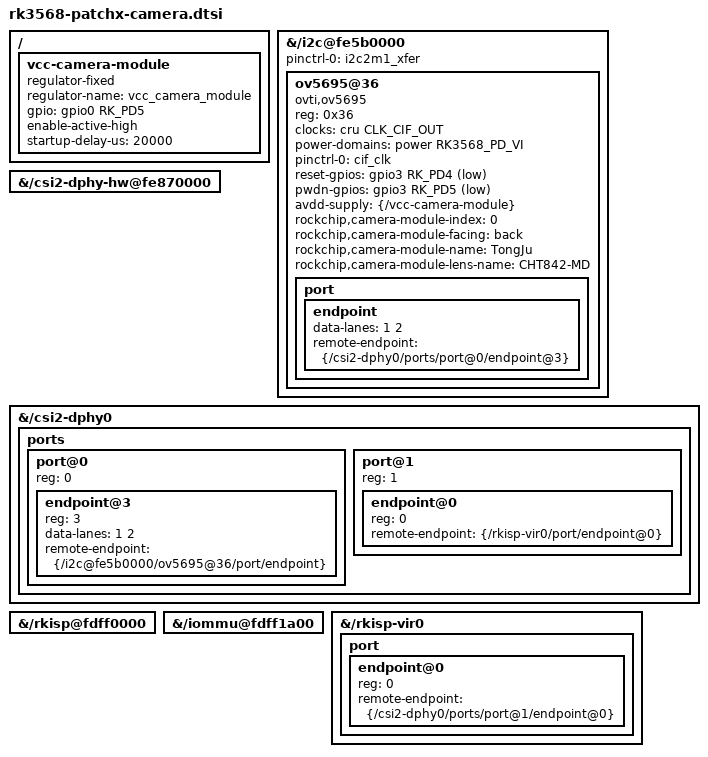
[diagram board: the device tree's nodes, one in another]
// SPDX-License-Identifier: (GPL-2.0+ OR MIT)
/*
 * OV5695 -> CSI2 DPHY0 -> RKISP virtual channel 0.
 * Matches the pre-overlay camera reset-polarity-v2 reference.
 * Explicit endpoint handles retain its reference numbers without adding symbols.
 */
/ {
	vcc-camera-module {
		compatible = "regulator-fixed";
		regulator-name = "vcc_camera_module";
		gpio = <&gpio0 RK_PD5 GPIO_ACTIVE_HIGH>;
		enable-active-high;
		startup-delay-us = <20000>;
		phandle = <0x301>;
	};
};

&{/i2c@fe5b0000} {
	status = "okay";
	pinctrl-0 = <&i2c2m1_xfer>;

	ov5695@36 {
		compatible = "ovti,ov5695";
		reg = <0x36>;
		status = "okay";
		clocks = <&cru CLK_CIF_OUT>;
		clock-names = "xvclk";
		power-domains = <&power RK3568_PD_VI>;
		pinctrl-names = "default";
		pinctrl-0 = <&cif_clk>;
		reset-gpios = <&gpio3 RK_PD4 GPIO_ACTIVE_LOW>;
		pwdn-gpios = <&gpio3 RK_PD5 GPIO_ACTIVE_LOW>;
		avdd-supply = <&{/vcc-camera-module}>;
		rockchip,camera-module-index = <0>;
		rockchip,camera-module-facing = "back";
		rockchip,camera-module-name = "TongJu";
		rockchip,camera-module-lens-name = "CHT842-MD";

		port {
			endpoint {
				data-lanes = <1 2>;
				remote-endpoint = <&{/csi2-dphy0/ports/port@0/endpoint@3}>;
				phandle = <0x302>;
			};
		};
	};
};

&{/csi2-dphy-hw@fe870000} {
	status = "okay";
};

&{/csi2-dphy0} {
	status = "okay";
	ports {
		#address-cells = <1>;
		#size-cells = <0>;
		port@0 {
			reg = <0>;
			#address-cells = <1>;
			#size-cells = <0>;
			endpoint@3 {
				reg = <3>;
				data-lanes = <1 2>;
				remote-endpoint = <&{/i2c@fe5b0000/ov5695@36/port/endpoint}>;
				phandle = <0x303>;
			};
		};
		port@1 {
			reg = <1>;
			#address-cells = <1>;
			#size-cells = <0>;
			endpoint@0 {
				reg = <0>;
				remote-endpoint = <&{/rkisp-vir0/port/endpoint@0}>;
				phandle = <0x304>;
			};
		};
	};
};

&{/rkisp@fdff0000} {
	status = "okay";
};

&{/iommu@fdff1a00} {
	status = "okay";
};

&{/rkisp-vir0} {
	status = "okay";
	port {
		#address-cells = <1>;
		#size-cells = <0>;
		endpoint@0 {
			reg = <0>;
			remote-endpoint = <&{/csi2-dphy0/ports/port@1/endpoint@0}>;
			phandle = <0x305>;
		};
	};
};
